# pse84 register map
Vendor: Cypress Semiconductor; Series: PSE84; File version: 1.0
CPU: CM33 r0p1, little endian, MPU, FPU, VTOR, 3 interrupt priority bits
Registers are 32-bit, read-write, reset 0x0 unless marked. A register's access mark holds for its fields unless they carry their own. Offsets are from the block's base; [hi:lo] are bit positions.

## ICACHE0 — CM33_0/1 CA APB interface
Base 0x42223000
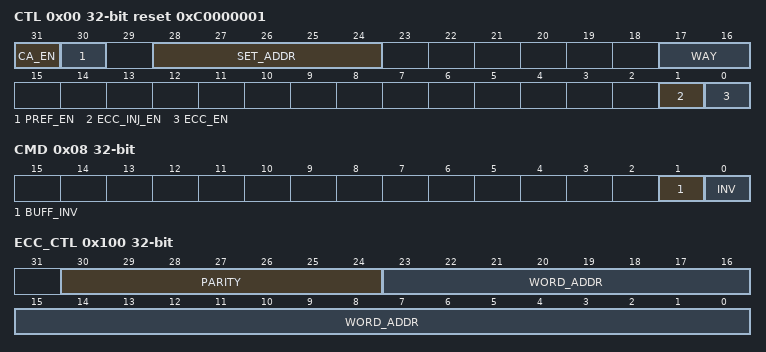
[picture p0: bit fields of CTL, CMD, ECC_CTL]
0x00 CTL reset 0xC0000001 — Cache control
  [31] CA_EN — Cache enable: 0: Disabled. The cache tag valid bits are reset to '0's and the cache LRU information is set to '1's (making way 0 the LRU way and way 3 the MRU way). 1: Enabled.
  [30] PREF_EN — Prefetch enable: 0: Disabled. 1: Enabled. Prefetching requires the cache to be enabled; i.e. ENABLED is '1'.
  [28:24] SET_ADDR — Specifies the cache set for which cache information is provided in STATUS0/1/2.
  [17:16] WAY — Specifies the cache way for which cache information is provided in STATUS0/1/2.
  [1] ECC_INJ_EN — Enable error injection for cache. When '1', the parity (ECC_CTL.PARITY[6:0]) is used when a cache refill is done to the ECC_CTL.WORD_ADDR[23:0] word address.
  [0] ECC_EN — Enable ECC checking for cache accesses: 0: Disabled. 1: Enabled.
0x08 CMD — Cache command
  [1] BUFF_INV — Invalidation of buffers (does not invalidate the caches). SW writes a '1' to clear the buffers. HW sets this field to '0' when the operation is completed.
  [0] INV — Invalidation of cahce and buffer. SW writes a '1' to clear the caches. HW sets this field to '0' when the operation is completed. The caches' LRU structures are also reset to their default state.
0x80 STATUS0 ro — Cache status 0
  [31:0] VALID32 — Sixteen valid bits of the cache line specified by CTL.WAY and CTL.SET_ADDR.
0x84 STATUS1 ro reset not defined — Cache status 1
  [31:0] TAG — Cache line address of the cache line specified by CTL.WAY and CTL.SET_ADDR.
0x88 STATUS2 ro reset 0x3F — Cache status 2
  [5:0] LRU — Six bit LRU representation of the cache set specified by CTL.SET_ADDR. The encoding of the field is as follows ('X_LRU_Y' indicates that way X is Less Recently Used than way Y): Bit 5: 0_LRU_1: way 0 less recently used than way 1. Bit 4: 0_LRU_2. Bit 3: 0_LRU_3. Bit 2: 1_LRU_2. Bit 1: 1_LRU_3. Bit 0: 2_LRU_3.
0x100 ECC_CTL — ECC control
  [30:24] PARITY — ECC parity to use for ECC error injection at address WORD_ADDR. - For cache SRAM ECC, the 7-bit parity PARITY[6:0] is for a 32-bit word.
  [23:0] WORD_ADDR — Specifies the word address where an error will be injected. - On a write transfer to this SRAM address and when the CTL.ECC_INJ_EN bit is '1', the parity (PARITY) is injected.

## MS5 — Master protection context control
Base 0x42294050
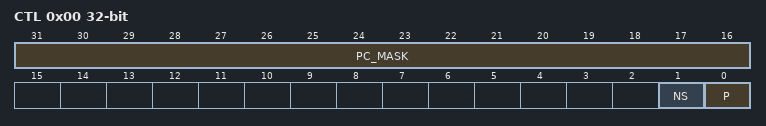
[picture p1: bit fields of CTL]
0x00 CTL — Master 'x' protection context control
  [31:16] PC_MASK — Protection context mask for protection contexts '15' down to '0'. Bit PC_MASK[i] indicates if the MS_PC_STRUCT[x].PC[3:0] protection context field can be set to the value 'i': - PC_MASK[i] is '0': MS_PC_STRUCT[x].PC[3:0] can NOT be set to 'i'; and PC[3:0] is not changed. - PC_MASK[i] is '1': MS_PC_STRUCT[x].PC[3:0] can be set to 'i'. Note: When CM33_0 CM33_PC_CTL.VALID[i] is '1' (the associated protection context handler is valid), write transfers to PC_MASK[i] always write '0', regardless of data written. This ensures that when valid protection context handlers are used to enter protection contexts 0, 1, 2 or 3 through HW (HW modifies MS_PC_STRUCT[x].PC[3:0] on entry of the handler), it is NOT possible for SW to enter those protection contexts.
  [1] NS — Master security controller configuration. 0: Bus master is secure. Master can send both secure and non-secure transfers. Accesses to secure addresses are not blocked and the security flag, HNONSEC, is set accordingly. 1: Bus master is non-secure. Master can send only non-secure transfers. Access to secure addresses, that is, outside the Uncheck regions, are blocked.
  [0] P — Privileged setting ('0': user mode; '1': privileged mode). Notes: This field is ONLY used for masters that do NOT provide their own user/privileged access control attribute. The default/reset field value provides privileged mode access capabilities.
